# ATSAMR21G18A device description
Architecture: CORTEX-M0PLUS; Family: SAMR; Series: SAMR21
Registers are 32-bit, read-write, reset 0x0 unless marked. A register's access mark holds for its fields unless they carry their own. Offsets are from the block's base; [hi:lo] are bit positions; {n}, {i} and the like mark numbered series; 'fields as' and 'values as' point back to an identical list.

## AC — Analog Comparators
Instances: AC 0x42004400
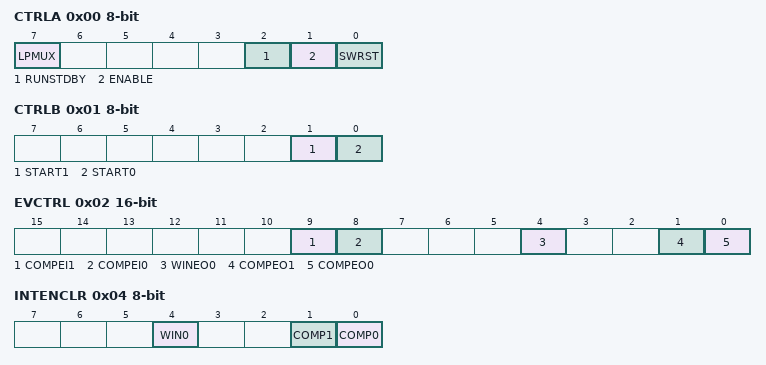
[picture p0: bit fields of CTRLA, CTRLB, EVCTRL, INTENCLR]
0x00 CTRLA 8-bit (WSYNC) — Control A
  [7] LPMUX — Low-Power Mux
  [2] RUNSTDBY — Run in Standby
  [1] ENABLE
  [0] SWRST — Software Reset
0x01 CTRLB 8-bit wo — Control B
  [1] START1 — Comparator 1 Start Comparison
  [0] START0 — Comparator 0 Start Comparison
0x02 EVCTRL 16-bit — Event Control
  [9] COMPEI1 — Comparator 1 Event Input
  [8] COMPEI0 — Comparator 0 Event Input
  [4] WINEO0 — Window 0 Event Output Enable
  [1] COMPEO1 — Comparator 1 Event Output Enable
  [0] COMPEO0 — Comparator 0 Event Output Enable
0x04 INTENCLR 8-bit (atomic clear) — Interrupt Enable Clear
  [4] WIN0 — Window 0 Interrupt Enable
  [1] COMP1 — Comparator 1 Interrupt Enable
  [0] COMP0 — Comparator 0 Interrupt Enable
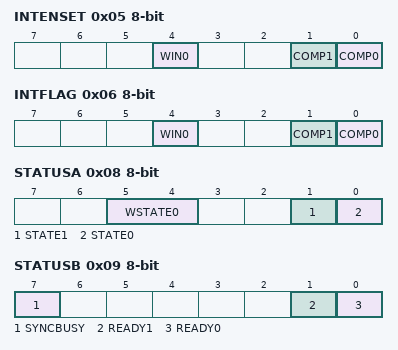
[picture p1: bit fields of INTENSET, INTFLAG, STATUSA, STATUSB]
0x05 INTENSET 8-bit (atomic set) — Interrupt Enable Set
  fields as INTENCLR
0x06 INTFLAG 8-bit (atomic clear) — Interrupt Flag Status and Clear
  [4] WIN0 — Window 0
  [1] COMP1 — Comparator 1
  [0] COMP0 — Comparator 0
0x08 STATUSA 8-bit ro
  [5:4] WSTATE0 — Window 0 Current State
    0=ABOVE (Signal is above window); 1=INSIDE (Signal is inside window); 2=BELOW (Signal is below window)
  [1] STATE1 — Comparator 1 Current State
  [0] STATE0 — Comparator 0 Current State
0x09 STATUSB 8-bit ro
  [7] SYNCBUSY — Synchronization Busy
  [1] READY1 — Comparator 1 Ready
  [0] READY0 — Comparator 0 Ready
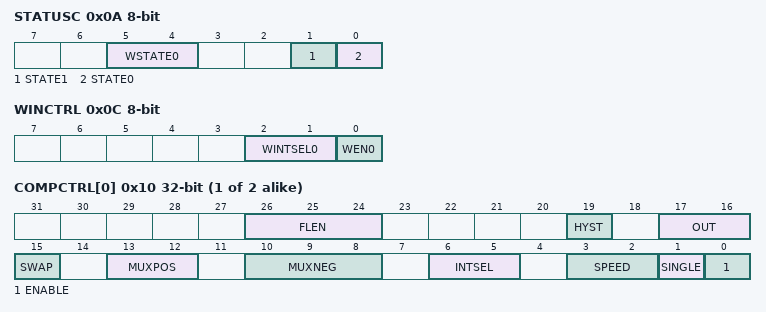
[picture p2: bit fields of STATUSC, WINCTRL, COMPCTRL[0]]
0x0A STATUSC 8-bit ro
  fields as STATUSA
0x0C WINCTRL 8-bit (WSYNC) — Window Control
  [2:1] WINTSEL0 — Window 0 Interrupt Selection
    0=ABOVE (Interrupt on signal above window); 1=INSIDE (Interrupt on signal inside window); 2=BELOW (Interrupt on signal below window); 3=OUTSIDE (Interrupt on signal outside window)
  [0] WEN0 — Window 0 Mode Enable
{0x10+4i} COMPCTRL[{i}] (i=0..1) (WSYNC) — Comparator Control n
  [26:24] FLEN — Filter Length
    0=OFF (No filtering); 1=MAJ3 (3-bit majority function (2 of 3)); 2=MAJ5 (5-bit majority function (3 of 5))
  [19] HYST — Hysteresis Enable
  [17:16] OUT — Output
    0=OFF (The output of COMPn is not routed to the COMPn I/O port); 1=ASYNC (The asynchronous output of COMPn is routed to the COMPn I/O port); 2=SYNC (The synchronous output (including filtering) of COMPn is routed to the COMPn I/O port)
  [15] SWAP — Swap Inputs and Invert
  [13:12] MUXPOS — Positive Input Mux Selection
    {v}=PIN{v} (I/O pin {v}) (v=0..3)
  [10:8] MUXNEG — Negative Input Mux Selection
    {v}=PIN{v} (I/O pin {v}) (v=0..3); 4=GND (Ground); 5=VSCALE (VDD scaler); 6=BANDGAP (Internal bandgap voltage)
  [6:5] INTSEL — Interrupt Selection
    0=TOGGLE (Interrupt on comparator output toggle); 1=RISING (Interrupt on comparator output rising); 2=FALLING (Interrupt on comparator output falling); 3=EOC (Interrupt on end of comparison (single-shot mode only))
  [3:2] SPEED — Speed Selection
    0=LOW (Low speed); 1=HIGH (High speed)
  [1] SINGLE — Single-Shot Mode
  [0] ENABLE
{0x20+i} SCALER[{i}] (i=0..1) 8-bit — Scaler n
  [5:0] VALUE — Scaler Value

## DMAC_DESCRIPTOR — Direct Memory Access Controller
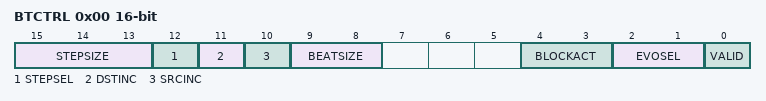
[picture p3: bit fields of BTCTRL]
0x00 BTCTRL 16-bit — Block Transfer Control
  [15:13] STEPSIZE — Address Increment Step Size
    0=Next ADDR = ADDR + (1<<BEATSIZE) * 1; 1=X2 (Next ADDR = ADDR + (1<<BEATSIZE) * 2); 2=X4 (Next ADDR = ADDR + (1<<BEATSIZE) * 4); 3=X8 (Next ADDR = ADDR + (1<<BEATSIZE) * 8); 4=X16 (Next ADDR = ADDR + (1<<BEATSIZE) * 16); 5=X32 (Next ADDR = ADDR + (1<<BEATSIZE) * 32); 6=X64 (Next ADDR = ADDR + (1<<BEATSIZE) * 64); 7=X128 (Next ADDR = ADDR + (1<<BEATSIZE) * 128)
  [12] STEPSEL — Step Selection
    0=DST (Step size settings apply to the destination address); 1=SRC (Step size settings apply to the source address)
  [11] DSTINC — Destination Address Increment Enable
  [10] SRCINC — Source Address Increment Enable
  [9:8] BEATSIZE
    0=BYTE (8-bit bus transfer); 1=HWORD (16-bit bus transfer); 2=WORD (32-bit bus transfer)
  [4:3] BLOCKACT — Block Action
    0=NOACT (Channel will be disabled if it is the last block transfer in the transaction); 1=INT (Channel will be disabled if it is the last block transfer in the transaction and block interrupt); 2=SUSPEND (Channel suspend operation is completed); 3=BOTH (Both channel suspend operation and block interrupt)
  [2:1] EVOSEL — Event Output Selection
    0=DISABLE (Event generation disabled); 1=BLOCK (Event strobe when block transfer complete); 3=BEAT (Event strobe when beat transfer complete)
  [0] VALID — Descriptor Valid
0x02 BTCNT 16-bit reset not defined — Block Transfer Count
0x04 SRCADDR reset not defined — Block Transfer Source Address
  [31:0] SRCADDR — Transfer Source Address
0x08 DSTADDR reset not defined — Block Transfer Destination Address
  [31:0] DSTADDR — Transfer Destination Address
0x0C DESCADDR reset not defined — Next Descriptor Address

## Notices in the file
Copyright (c) 2018 Microchip Technology Inc.
SPDX-License-Identifier: Apache-2.0
Licensed under the Apache License, Version 2.0 (the "License");
you may not use this file except in compliance with the License.
You may obtain a copy of the License at
http://www.apache.org/licenses/LICENSE-2.0
Unless required by applicable law or agreed to in writing, software
distributed under the License is distributed on an "AS IS" BASIS,
WITHOUT WARRANTIES OR CONDITIONS OF ANY KIND, either express or implied.
See the License for the specific language governing permissions and
limitations under the License.
